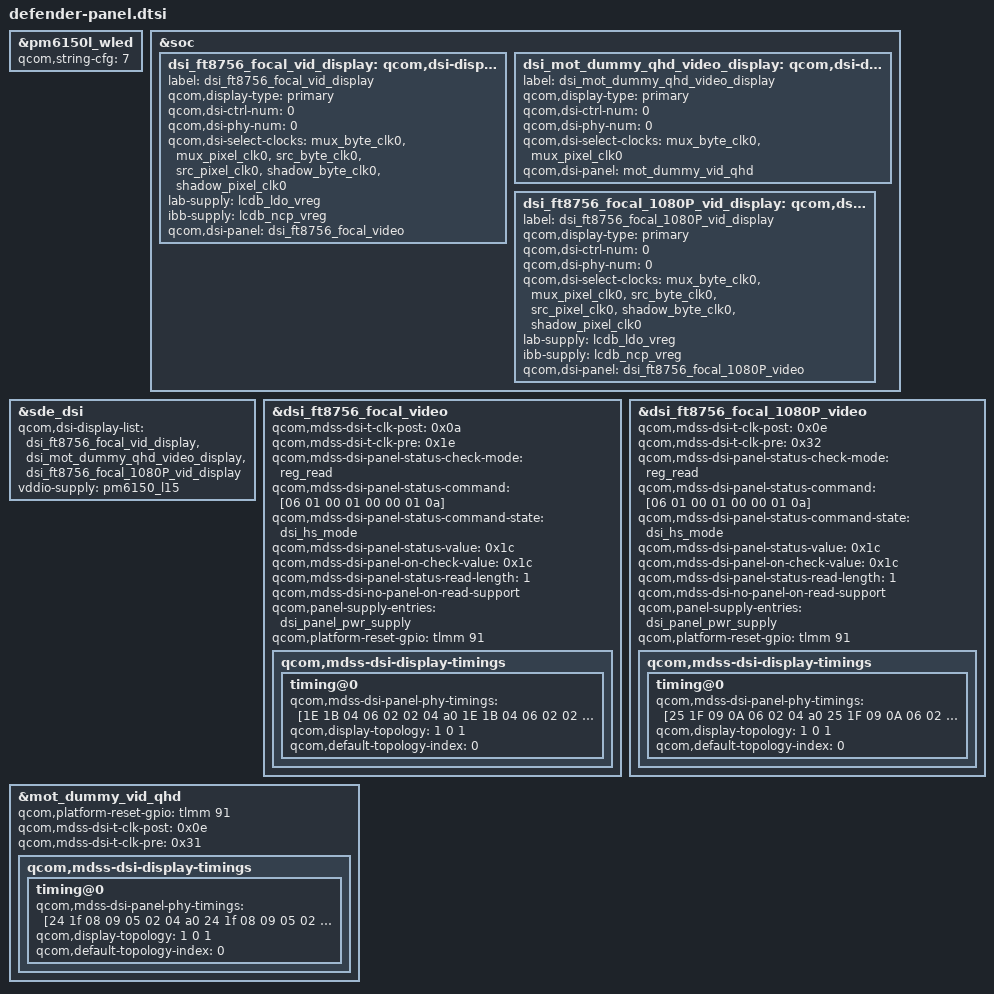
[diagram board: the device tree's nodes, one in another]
/*
 * Copyright (c) 2019, The Linux Foundation. All rights reserved.
 *
 * This program is free software; you can redistribute it and/or modify
 * it under the terms of the GNU General Public License version 2 and
 * only version 2 as published by the Free Software Foundation.
 *
 * This program is distributed in the hope that it will be useful,
 * but WITHOUT ANY WARRANTY; without even the implied warranty of
 * MERCHANTABILITY or FITNESS FOR A PARTICULAR PURPOSE.  See the
 * GNU General Public License for more details.
 */

#include "dsi-panel-mot-ft8756-focal-720p-video.dtsi"
#include "dsi-panel-mot-ft8756-focal-1080P-video.dtsi"

&pm6150l_wled {
	qcom,string-cfg= <7>;
	status = "ok";
};
&soc {
	dsi_ft8756_focal_vid_display: qcom,dsi-display@10 {
		label = "dsi_ft8756_focal_vid_display";
		qcom,display-type = "primary";

		qcom,dsi-ctrl-num = <0>;
		qcom,dsi-phy-num = <0>;
		qcom,dsi-select-clocks = "mux_byte_clk0", "mux_pixel_clk0",
			"src_byte_clk0", "src_pixel_clk0",
			"shadow_byte_clk0", "shadow_pixel_clk0";
		lab-supply = <&lcdb_ldo_vreg>;
		ibb-supply = <&lcdb_ncp_vreg>;
		qcom,dsi-panel = <&dsi_ft8756_focal_video>;
	};

	dsi_mot_dummy_qhd_video_display: qcom,dsi-display@11 {
		label = "dsi_mot_dummy_qhd_video_display";
		qcom,display-type = "primary";

		qcom,dsi-ctrl-num = <0>;
		qcom,dsi-phy-num = <0>;
		qcom,dsi-select-clocks = "mux_byte_clk0", "mux_pixel_clk0";

		qcom,dsi-panel = <&mot_dummy_vid_qhd>;
	};
	dsi_ft8756_focal_1080P_vid_display: qcom,dsi-display@12 {
		label = "dsi_ft8756_focal_1080P_vid_display";
		qcom,display-type = "primary";

		qcom,dsi-ctrl-num = <0>;
		qcom,dsi-phy-num = <0>;
		qcom,dsi-select-clocks = "mux_byte_clk0", "mux_pixel_clk0",
			"src_byte_clk0", "src_pixel_clk0",
			"shadow_byte_clk0", "shadow_pixel_clk0";
		lab-supply = <&lcdb_ldo_vreg>;
		ibb-supply = <&lcdb_ncp_vreg>;
		qcom,dsi-panel = <&dsi_ft8756_focal_1080P_video>;
	};

};

&sde_dsi {
	qcom,dsi-display-list = <
				  &dsi_ft8756_focal_vid_display
                                  &dsi_mot_dummy_qhd_video_display
				  &dsi_ft8756_focal_1080P_vid_display>;
        /delete-property/ qcom,platform-te-gpio;
	/delete-property/vddio-supply;

	vddio-supply = <&pm6150_l15>;
};


&dsi_ft8756_focal_video {
	qcom,mdss-dsi-t-clk-post = <0x0a>;
	qcom,mdss-dsi-t-clk-pre = <0x1e>;
	/*qcom,dsi-supported-dfps-list = <60 55 48>;
	qcom,mdss-dsi-pan-enable-dynamic-fps;
	qcom,mdss-dsi-pan-fps-update =
		"dfps_immediate_porch_mode_vfp";*/
	qcom,mdss-dsi-panel-status-check-mode = "reg_read";
	qcom,mdss-dsi-panel-status-command = [06 01 00 01 00 00 01 0a];
	qcom,mdss-dsi-panel-status-command-state = "dsi_hs_mode";
	qcom,mdss-dsi-panel-status-value = <0x1c>;
	qcom,mdss-dsi-panel-on-check-value = <0x1c>;
	qcom,mdss-dsi-panel-status-read-length = <1>;
	qcom,mdss-dsi-no-panel-on-read-support;
	//qcom,dsi-dyn-clk-enable;
	//qcom,dsi-dyn-clk-list =
	//	<1005903360 989138304 993329568 997520832 1001712096>;
	qcom,mdss-dsi-display-timings {
		timing@0{
			qcom,mdss-dsi-panel-phy-timings =
				[1E 1B 04 06 02 02 04 a0
				1E 1B 04 06 02 02 04 a0
				1E 1B 04 06 02 02 04 a0
				1E 1B 04 06 02 02 04 a0
				1E 0E 04 05 02 03 04 a0];

			qcom,display-topology = <1 0 1>;
			qcom,default-topology-index = <0>;
		};
	};
};

&dsi_ft8756_focal_video {
	qcom,panel-supply-entries = <&dsi_panel_pwr_supply>;
	qcom,platform-reset-gpio = <&tlmm 91 0>;
};

&dsi_ft8756_focal_1080P_video {
	qcom,mdss-dsi-t-clk-post = <0x0e>;
	qcom,mdss-dsi-t-clk-pre = <0x32>;
	/*qcom,dsi-supported-dfps-list = <60 55 48>;
	qcom,mdss-dsi-pan-enable-dynamic-fps;
	qcom,mdss-dsi-pan-fps-update =
		"dfps_immediate_porch_mode_vfp";*/
	qcom,mdss-dsi-panel-status-check-mode = "reg_read";
	qcom,mdss-dsi-panel-status-command = [06 01 00 01 00 00 01 0a];
	qcom,mdss-dsi-panel-status-command-state = "dsi_hs_mode";
	qcom,mdss-dsi-panel-status-value = <0x1c>;
	qcom,mdss-dsi-panel-on-check-value = <0x1c>;
	qcom,mdss-dsi-panel-status-read-length = <1>;
	qcom,mdss-dsi-no-panel-on-read-support;
	//qcom,dsi-dyn-clk-enable;
	//qcom,dsi-dyn-clk-list =
	//	<1005903360 989138304 993329568 997520832 1001712096>;
	qcom,mdss-dsi-display-timings {
		timing@0{
			qcom,mdss-dsi-panel-phy-timings =
				[25 1F 09 0A 06 02 04 a0
				25 1F 09 0A 06 02 04 a0
				25 1F 09 0A 06 02 04 a0
				25 1F 09 0A 06 02 04 a0
				25 1E 08 0A 06 03 04 a0];

			qcom,display-topology = <1 0 1>;
			qcom,default-topology-index = <0>;
		};
	};
};

&dsi_ft8756_focal_1080P_video {
	qcom,panel-supply-entries = <&dsi_panel_pwr_supply>;
	qcom,platform-reset-gpio = <&tlmm 91 0>;
};

&mot_dummy_vid_qhd {
	//qcom,platform-te-gpio = <&tlmm 90 0>;
	qcom,platform-reset-gpio = <&tlmm 91 0>;

	qcom,mdss-dsi-t-clk-post = <0x0e>;
	qcom,mdss-dsi-t-clk-pre = <0x31>;
	qcom,mdss-dsi-display-timings {
		timing@0{
			qcom,mdss-dsi-panel-phy-timings =
				[24 1f 08 09 05 02 04 a0
				24 1f 08 09 05 02 04 a0
				24 1f 08 09 05 02 04 a0
				24 1f 08 09 05 02 04 a0
				24 1c 08 09 05 02 04 a0];

			qcom,display-topology = <1 0 1>;
			qcom,default-topology-index = <0>;
		};
	};
};

